# TEST123 register map
File version: 1.0
CPU: Test r0p0, little endian, no MPU, no FPU
Registers are 32-bit, read-only, reset 0x0 unless marked. A register's access mark holds for its fields unless they carry their own. Offsets are from the block's base; lines under a group give offsets from that group; [hi:lo] are bit positions; {n}, {i} and the like mark numbered series; 'fields as' and 'values as' point back to an identical list; <NAME> marks a mode.

## Memory map
0x00001234 TEST1 — TEST1 registers
0x00002000 TEST2 — TEST2 registers

## Interrupts
81 TEST (TEST1) — TEST interrupt
85 TEST2 — TEST2 interrupt

## TEST1 — TEST1 registers
Base 0x00001234
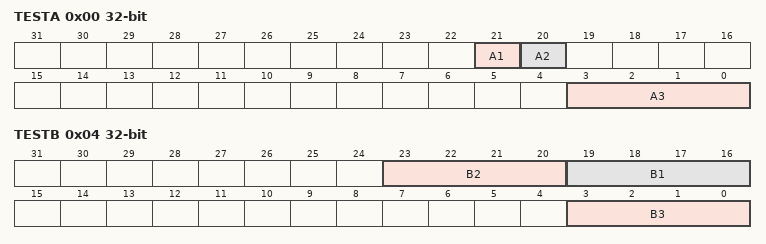
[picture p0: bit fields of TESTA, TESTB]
0x00 TESTA
  [21] A1 — Bit A1
  [20] A2 — Bit A2
  [3:0] A3 — Bit A3
0x04 TESTB
  [23:20] B2 — Bit B2
  [19:16] B1 — Bit B1
  [3:0] B3 — Bit B3

## TEST2 — TEST2 registers
Base 0x00002000
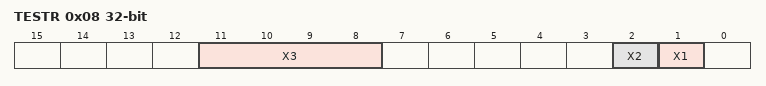
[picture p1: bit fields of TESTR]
0x08 TESTR
  [11:8] X3 — Bit X3
  [2] X2 — Bit X2
  [1] X1 — Bit X1
0x10 TESTU
  [31:0] W — Bit W1
